# M036 register map
File version: 2.0.2.1
Registers are 32-bit, read-write, reset 0x0 unless marked. A register's access mark holds for its fields unless they carry their own. Offsets are from the block's base; [hi:lo] are bit positions; {n}, {i} and the like mark numbered series.

## DMACRQ — DMAC Request Control
Base 0x4005F000
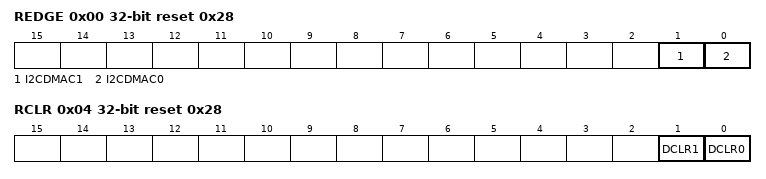
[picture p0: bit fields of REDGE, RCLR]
0x00 REDGE reset 0x28 — DMAC Request Edge setting Register
  [1] I2CDMAC1, [0] I2CDMAC0
0x04 RCLR wo reset 0x28 — DMAC Request Clear Register
  [1] DCLR1, [0] DCLR0

## T16A0 — 16-bit TimerA
Base 0x4008D000
Same registers: T16A1 0x4008E000, T16A2 0x4008F000, T16A3 0x40090000
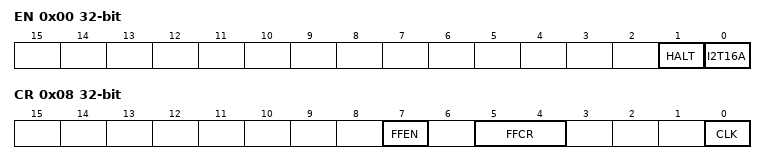
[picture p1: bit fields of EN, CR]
0x00 EN — Enable Register
  [1] HALT, [0] I2T16A
0x04 RUN
  [0] RUN
0x08 CR — Control Register
  [7] FFEN, [5:4] FFCR wo, [0] CLK
0x0C RG — Timer Register
  [15:0] RG
0x10 CP ro — Capture Register
  [15:0] CP

## I2C0 — I2C
Base 0x400A0000
Same registers: I2C1 0x400A1000
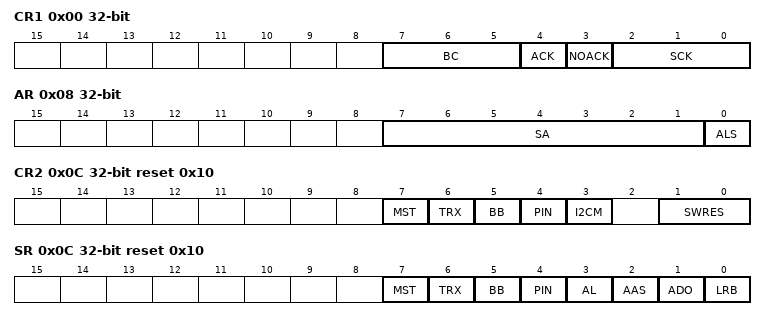
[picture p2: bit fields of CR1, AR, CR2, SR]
0x00 CR1 — I2C Control Register 1
  [7:5] BC, [4] ACK, [3] NOACK, [2:0] SCK
0x04 DBR — Data Buffer Register
  [7:0] DB
0x08 AR — Bus address Register
  [7:1] SA, [0] ALS
0x0C CR2 wo reset 0x10 — Control Register 2
  [7] MST, [6] TRX, [5] BB, [4] PIN, [3] I2CM, [1:0] SWRES
0x0C SR ro reset 0x10 — Status Register
  [7] MST, [6] TRX, [5] BB, [4] PIN, [3] AL, [2] AAS, [1] ADO, [0] LRB
0x10 PRS — Prescaler clcok setting Register
  [4:0] PRSCK
0x14 IE — Interrupt Enable Register
  [0] IE
0x18 IR — Interrupt Register
  [0] ISIC

## PA — Port A
Base 0x400C0000
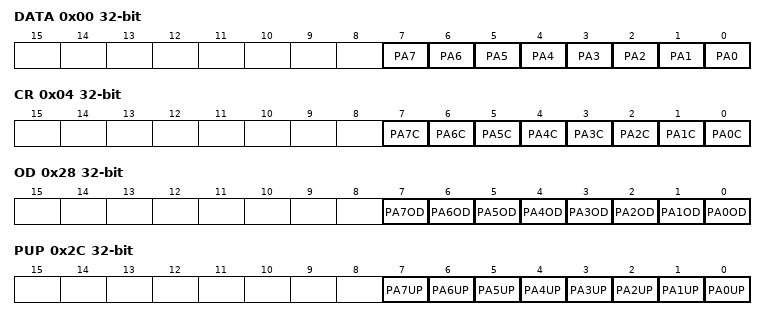
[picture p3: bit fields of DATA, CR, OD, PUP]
0x00 DATA — PA Data Register
  [n] PA{n} (n=0..7)
0x04 CR — PA Control Register
  [n] PA{n}C (n=0..7)
0x28 OD — PA Open Drain Control Register
  [n] PA{n}OD (n=0..7)
0x2C PUP — PA Pull-up Control Register
  [n] PA{n}UP (n=0..7)
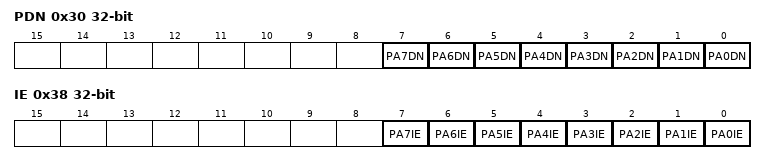
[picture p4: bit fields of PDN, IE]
0x30 PDN — PA Pull-Down Control Register
  [n] PA{n}DN (n=0..7)
0x38 IE — PA Input Enable Control Register
  [n] PA{n}IE (n=0..7)

## PB — Port B
Base 0x400C0100
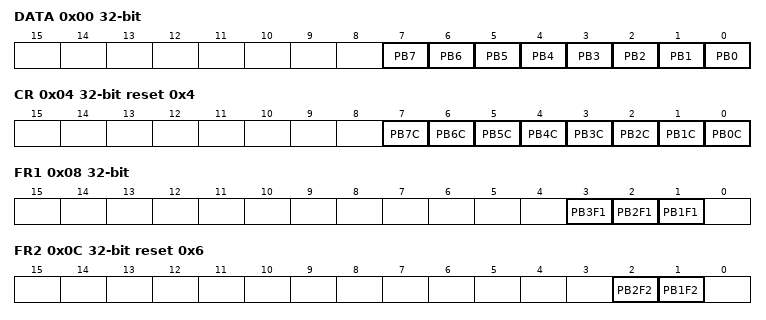
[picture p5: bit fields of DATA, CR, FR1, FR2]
0x00 DATA — PB Data Register
  [n] PB{n} (n=0..7)
0x04 CR reset 0x4 — PB Control Register
  [n] PB{n}C (n=0..7)
0x08 FR1 — PB Function Register 1
  [3] PB3F1, [2] PB2F1, [1] PB1F1
0x0C FR2 reset 0x6 — PB Function Register 2
  [2] PB2F2, [1] PB1F2
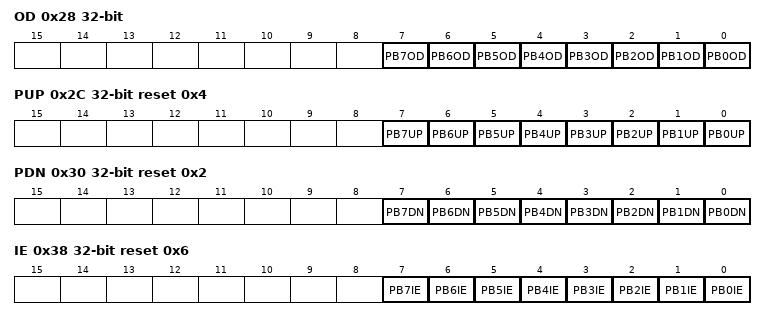
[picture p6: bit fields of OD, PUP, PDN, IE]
0x28 OD — PB Open Drain Control Register
  [n] PB{n}OD (n=0..7)
0x2C PUP reset 0x4 — PB Pull-up Control Register
  [n] PB{n}UP (n=0..7)
0x30 PDN reset 0x2 — PB Pull-Down Control Register
  [n] PB{n}DN (n=0..7)
0x38 IE reset 0x6 — PB Input Enable Control Register
  [n] PB{n}IE (n=0..7)

## PC — Port C
Base 0x400C0200
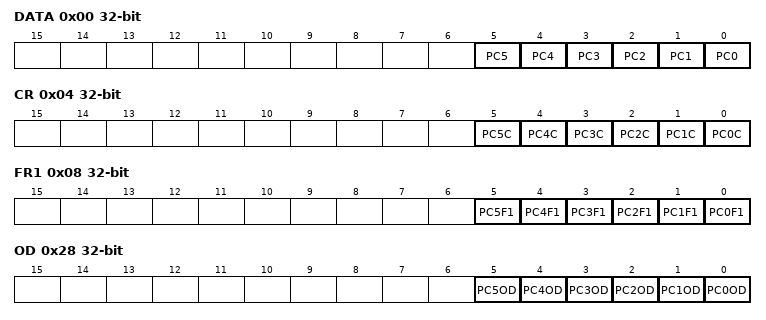
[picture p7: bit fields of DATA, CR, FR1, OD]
0x00 DATA — PC Data Register
  [n] PC{n} (n=0..5)
0x04 CR — PC Control Register
  [n] PC{n}C (n=0..5)
0x08 FR1 — PC Function Register 1
  [n] PC{n}F1 (n=0..5)
0x28 OD — PC Open Drain Control Register
  [n] PC{n}OD (n=0..5)
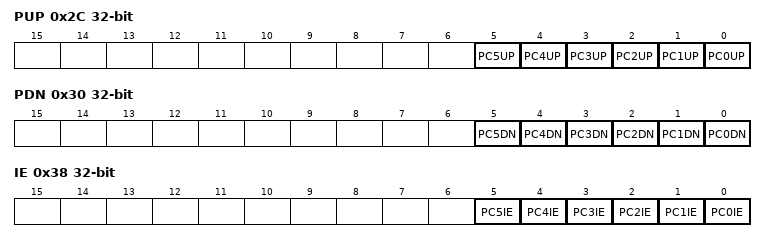
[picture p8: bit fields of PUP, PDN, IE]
0x2C PUP — PC Pull-up Control Register
  [n] PC{n}UP (n=0..5)
0x30 PDN — PC Pull-Down Control Register
  [n] PC{n}DN (n=0..5)
0x38 IE — PC Input Enable Control Register
  [n] PC{n}IE (n=0..5)

## PD — Port D
Base 0x400C0300
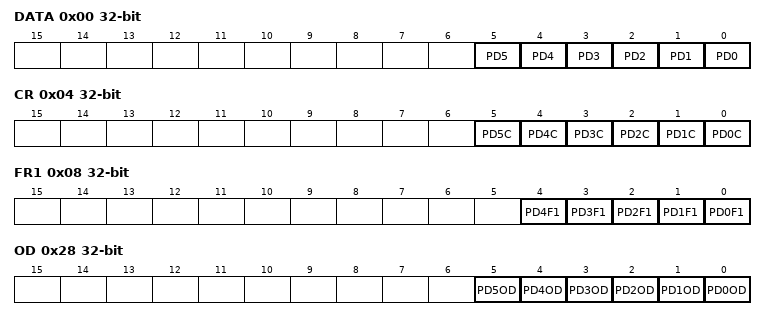
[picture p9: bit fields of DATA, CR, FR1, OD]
0x00 DATA — PD Data Register
  [n] PD{n} (n=0..5)
0x04 CR — PD Control Register
  [n] PD{n}C (n=0..5)
0x08 FR1 — PD Function Register 1
  [n] PD{n}F1 (n=0..4)
0x28 OD — PD Open Drain Control Register
  [n] PD{n}OD (n=0..5)
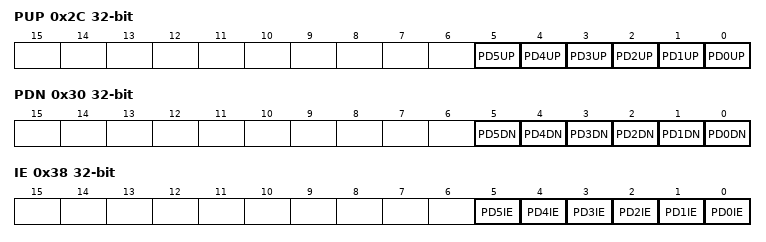
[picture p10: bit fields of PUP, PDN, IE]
0x2C PUP — PD Pull-up Control Register
  [n] PD{n}UP (n=0..5)
0x30 PDN — PD Pull-Down Control Register
  [n] PD{n}DN (n=0..5)
0x38 IE — PD Input Enable Control Register
  [n] PD{n}IE (n=0..5)

## PE — Port E
Base 0x400C0400
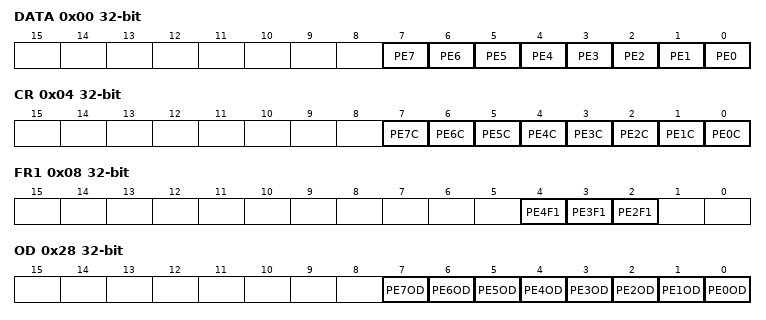
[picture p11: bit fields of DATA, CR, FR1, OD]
0x00 DATA — PE Data Register
  [n] PE{n} (n=0..7)
0x04 CR — PE Control Register
  [n] PE{n}C (n=0..7)
0x08 FR1 — PE Function Register 1
  [4] PE4F1, [3] PE3F1, [2] PE2F1
0x28 OD — PE Open Drain Control Register
  [n] PE{n}OD (n=0..7)
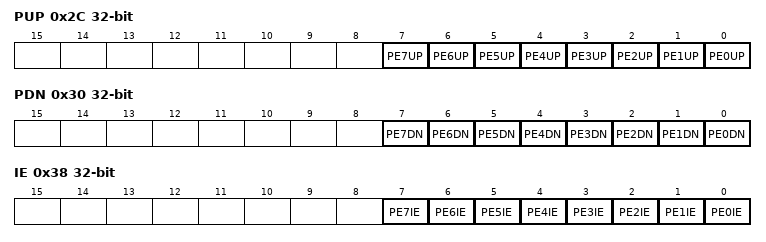
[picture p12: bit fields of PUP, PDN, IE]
0x2C PUP — PE Pull-up Control Register
  [n] PE{n}UP (n=0..7)
0x30 PDN — PE Pull-Down Control Register
  [n] PE{n}DN (n=0..7)
0x38 IE — PE Input Enable Control Register
  [n] PE{n}IE (n=0..7)

## PF — Port F
Base 0x400C0500
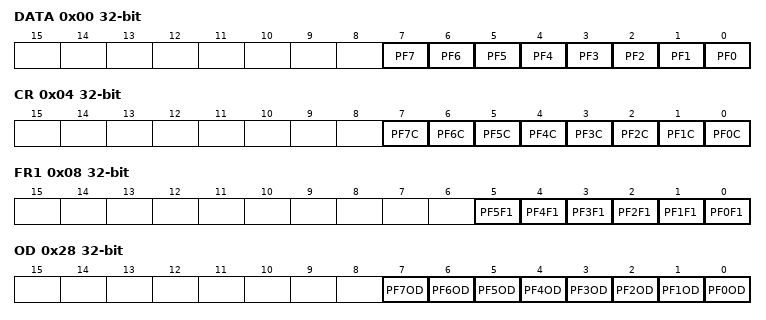
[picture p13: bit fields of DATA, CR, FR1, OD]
0x00 DATA — PF Data Register
  [n] PF{n} (n=0..7)
0x04 CR — PF Control Register
  [n] PF{n}C (n=0..7)
0x08 FR1 — PF Function Register 1
  [n] PF{n}F1 (n=0..5)
0x28 OD — PF Open Drain Control Register
  [n] PF{n}OD (n=0..7)
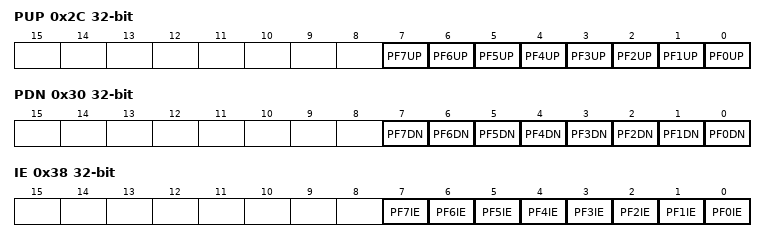
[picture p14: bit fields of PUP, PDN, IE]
0x2C PUP — PF Pull-up Control Register
  [n] PF{n}UP (n=0..7)
0x30 PDN — PF Pull-Down Control Register
  [n] PF{n}DN (n=0..7)
0x38 IE — PF Input Enable Control Register
  [n] PF{n}IE (n=0..7)
